# ddr_emif register map
Vendor: Texas Instruments
Peripheral module from a debugger description file (folder Keystone).
Registers are 32-bit, read-write, no defined reset value unless marked. A register's access mark holds for its fields unless they carry their own. Offsets are as the file gives them; lines under a group give offsets from that group; [hi:lo] are bit positions; {n}, {i} and the like mark numbered series; 'fields as' and 'values as' point back to an identical list; <NAME> marks a mode.

## DDR_EMIF
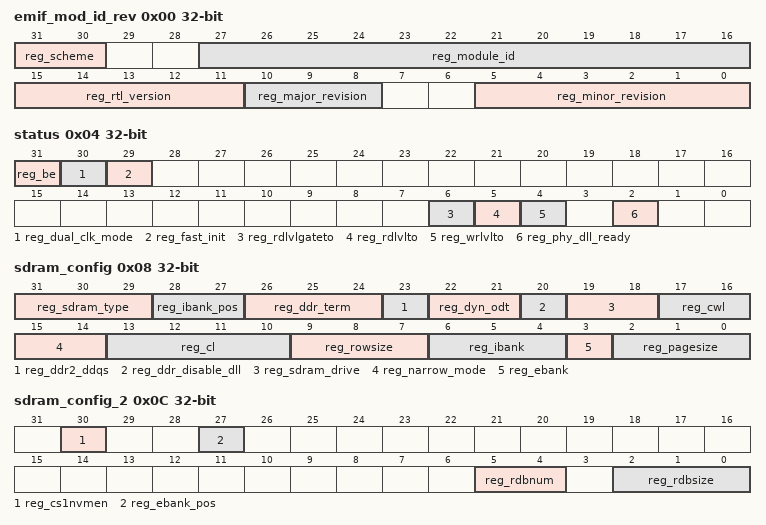
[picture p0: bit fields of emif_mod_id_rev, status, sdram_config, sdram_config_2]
0x00 emif_mod_id_rev
  [31:30] reg_scheme, [27:16] reg_module_id, [15:11] reg_rtl_version, [10:8] reg_major_revision, [5:0] reg_minor_revision
0x04 status
  [31] reg_be, [30] reg_dual_clk_mode, [29] reg_fast_init, [6] reg_rdlvlgateto, [5] reg_rdlvlto, [4] reg_wrlvlto, [2] reg_phy_dll_ready
0x08 sdram_config
  [31:29] reg_sdram_type, [28:27] reg_ibank_pos, [26:24] reg_ddr_term, [23] reg_ddr2_ddqs, [22:21] reg_dyn_odt, [20] reg_ddr_disable_dll, [19:18] reg_sdram_drive, [17:16] reg_cwl, [15:14] reg_narrow_mode, [13:10] reg_cl, [9:7] reg_rowsize, [6:4] reg_ibank, [3] reg_ebank, [2:0] reg_pagesize
0x0C sdram_config_2
  [30] reg_cs1nvmen, [27] reg_ebank_pos, [5:4] reg_rdbnum, [2:0] reg_rdbsize
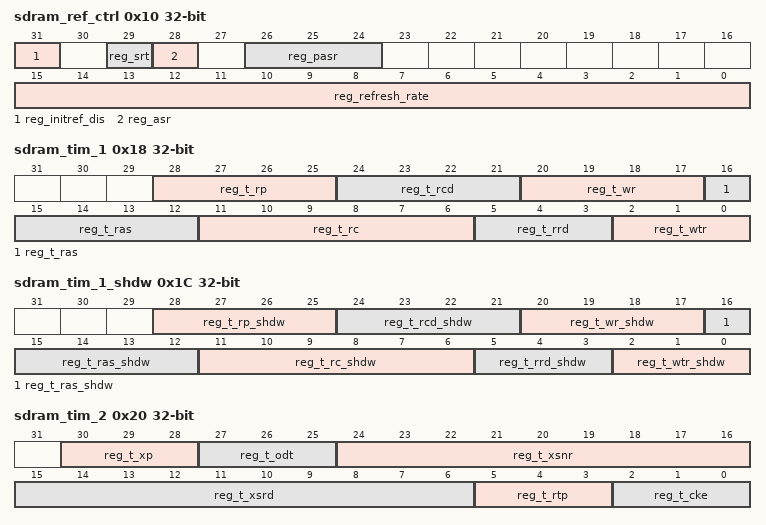
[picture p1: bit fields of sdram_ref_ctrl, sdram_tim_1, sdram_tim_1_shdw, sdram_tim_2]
0x10 sdram_ref_ctrl
  [31] reg_initref_dis, [29] reg_srt, [28] reg_asr, [26:24] reg_pasr, [15:0] reg_refresh_rate
0x14 sdram_ref_ctrl_shdw
  [15:0] reg_refresh_rate_shdw
0x18 sdram_tim_1
  [28:25] reg_t_rp, [24:21] reg_t_rcd, [20:17] reg_t_wr, [16:12] reg_t_ras, [11:6] reg_t_rc, [5:3] reg_t_rrd, [2:0] reg_t_wtr
0x1C sdram_tim_1_shdw
  [28:25] reg_t_rp_shdw, [24:21] reg_t_rcd_shdw, [20:17] reg_t_wr_shdw, [16:12] reg_t_ras_shdw, [11:6] reg_t_rc_shdw, [5:3] reg_t_rrd_shdw, [2:0] reg_t_wtr_shdw
0x20 sdram_tim_2
  [30:28] reg_t_xp, [27:25] reg_t_odt, [24:16] reg_t_xsnr, [15:6] reg_t_xsrd, [5:3] reg_t_rtp, [2:0] reg_t_cke
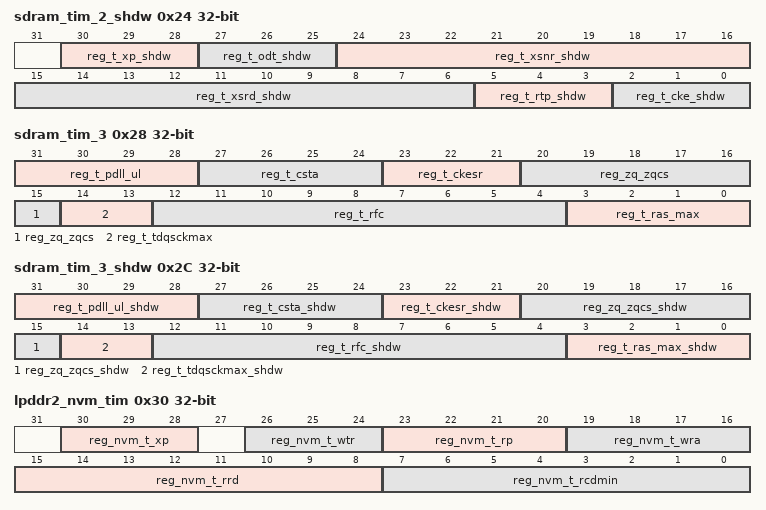
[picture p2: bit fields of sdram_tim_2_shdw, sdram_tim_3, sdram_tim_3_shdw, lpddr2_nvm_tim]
0x24 sdram_tim_2_shdw
  [30:28] reg_t_xp_shdw, [27:25] reg_t_odt_shdw, [24:16] reg_t_xsnr_shdw, [15:6] reg_t_xsrd_shdw, [5:3] reg_t_rtp_shdw, [2:0] reg_t_cke_shdw
0x28 sdram_tim_3
  [31:28] reg_t_pdll_ul, [27:24] reg_t_csta, [23:21] reg_t_ckesr, [20:15] reg_zq_zqcs, [14:13] reg_t_tdqsckmax, [12:4] reg_t_rfc, [3:0] reg_t_ras_max
0x2C sdram_tim_3_shdw
  [31:28] reg_t_pdll_ul_shdw, [27:24] reg_t_csta_shdw, [23:21] reg_t_ckesr_shdw, [20:15] reg_zq_zqcs_shdw, [14:13] reg_t_tdqsckmax_shdw, [12:4] reg_t_rfc_shdw, [3:0] reg_t_ras_max_shdw
0x30 lpddr2_nvm_tim
  [30:28] reg_nvm_t_xp, [26:24] reg_nvm_t_wtr, [23:20] reg_nvm_t_rp, [19:16] reg_nvm_t_wra, [15:8] reg_nvm_t_rrd, [7:0] reg_nvm_t_rcdmin
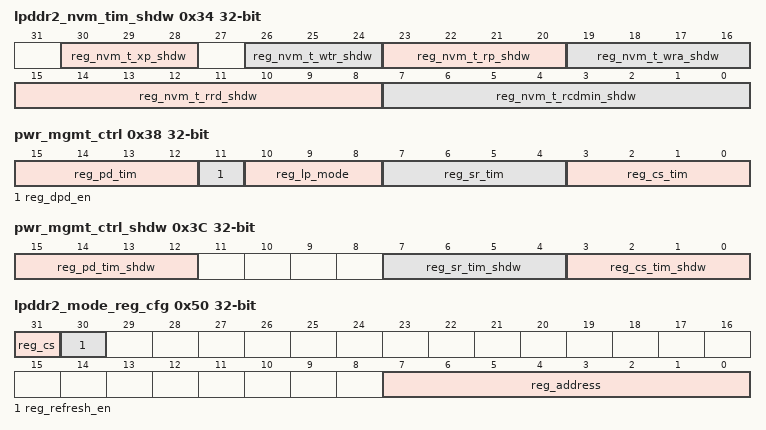
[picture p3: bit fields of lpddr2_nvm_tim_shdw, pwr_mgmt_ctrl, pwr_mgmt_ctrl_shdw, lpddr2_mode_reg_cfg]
0x34 lpddr2_nvm_tim_shdw
  [30:28] reg_nvm_t_xp_shdw, [26:24] reg_nvm_t_wtr_shdw, [23:20] reg_nvm_t_rp_shdw, [19:16] reg_nvm_t_wra_shdw, [15:8] reg_nvm_t_rrd_shdw, [7:0] reg_nvm_t_rcdmin_shdw
0x38 pwr_mgmt_ctrl
  [15:12] reg_pd_tim, [11] reg_dpd_en, [10:8] reg_lp_mode, [7:4] reg_sr_tim, [3:0] reg_cs_tim
0x3C pwr_mgmt_ctrl_shdw
  [15:12] reg_pd_tim_shdw, [7:4] reg_sr_tim_shdw, [3:0] reg_cs_tim_shdw
0x40 lpddr2_mode_reg_data
  [6:0] reg_value_0
0x50 lpddr2_mode_reg_cfg
  [31] reg_cs, [30] reg_refresh_en, [7:0] reg_address
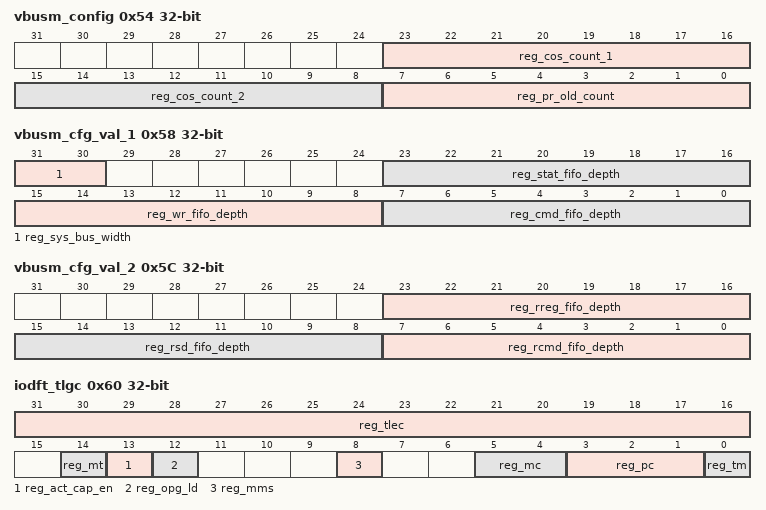
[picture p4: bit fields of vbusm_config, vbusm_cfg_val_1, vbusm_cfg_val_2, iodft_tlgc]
0x54 vbusm_config
  [23:16] reg_cos_count_1, [15:8] reg_cos_count_2, [7:0] reg_pr_old_count
0x58 vbusm_cfg_val_1
  [31:30] reg_sys_bus_width, [23:16] reg_stat_fifo_depth, [15:8] reg_wr_fifo_depth, [7:0] reg_cmd_fifo_depth
0x5C vbusm_cfg_val_2
  [23:16] reg_rreg_fifo_depth, [15:8] reg_rsd_fifo_depth, [7:0] reg_rcmd_fifo_depth
0x60 iodft_tlgc
  [31:16] reg_tlec, [14] reg_mt, [13] reg_act_cap_en, [12] reg_opg_ld, [8] reg_mms, [5:4] reg_mc, [3:1] reg_pc, [0] reg_tm
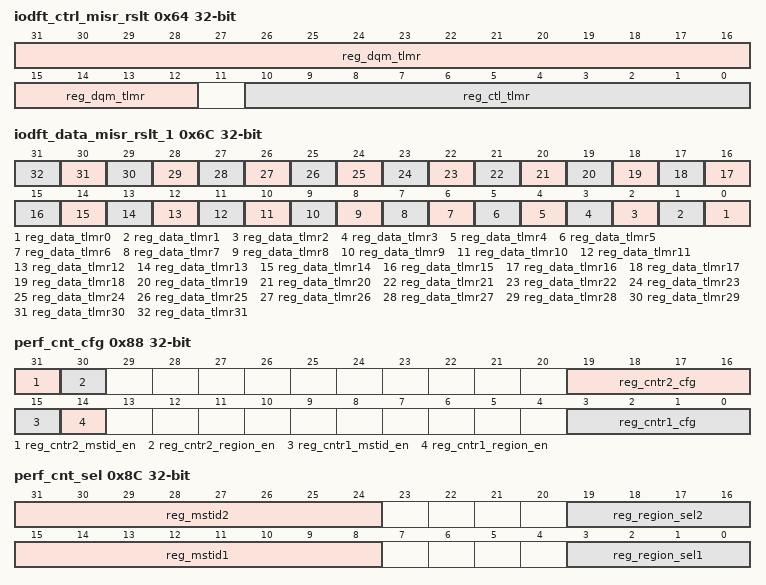
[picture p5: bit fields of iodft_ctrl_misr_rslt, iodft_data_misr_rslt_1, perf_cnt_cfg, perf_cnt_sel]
0x64 iodft_ctrl_misr_rslt
  [31:12] reg_dqm_tlmr, [10:0] reg_ctl_tlmr
0x68 iodft_addr_misr_rslt
  [20:0] reg_addr_tlmr
0x6C iodft_data_misr_rslt_1
  [n] reg_data_tlmr{n} (n=0..31)
{0x68+4i} iodft_data_misr_rslt_{i} access not given (i=2..5)
0x80 perf_cnt_1
  [31:0] reg_counter1
0x84 perf_cnt_2
  [31:0] reg_counter2
0x88 perf_cnt_cfg
  [31] reg_cntr2_mstid_en, [30] reg_cntr2_region_en, [19:16] reg_cntr2_cfg, [15] reg_cntr1_mstid_en, [14] reg_cntr1_region_en, [3:0] reg_cntr1_cfg
0x8C perf_cnt_sel
  [31:24] reg_mstid2, [19:16] reg_region_sel2, [15:8] reg_mstid1, [3:0] reg_region_sel1
0x90 perf_cnt_tim
  [31:0] reg_total_time
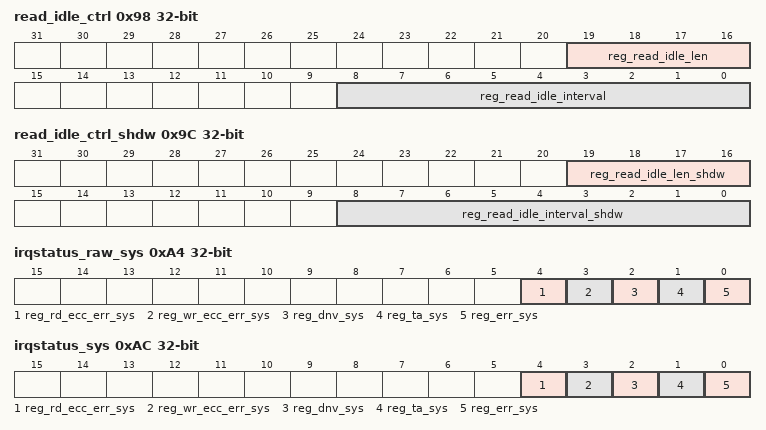
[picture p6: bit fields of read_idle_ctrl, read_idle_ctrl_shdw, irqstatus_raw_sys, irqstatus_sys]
0x98 read_idle_ctrl
  [19:16] reg_read_idle_len, [8:0] reg_read_idle_interval
0x9C read_idle_ctrl_shdw
  [19:16] reg_read_idle_len_shdw, [8:0] reg_read_idle_interval_shdw
0xA4 irqstatus_raw_sys
  [4] reg_rd_ecc_err_sys, [3] reg_wr_ecc_err_sys, [2] reg_dnv_sys, [1] reg_ta_sys, [0] reg_err_sys
0xAC irqstatus_sys
  fields as irqstatus_raw_sys
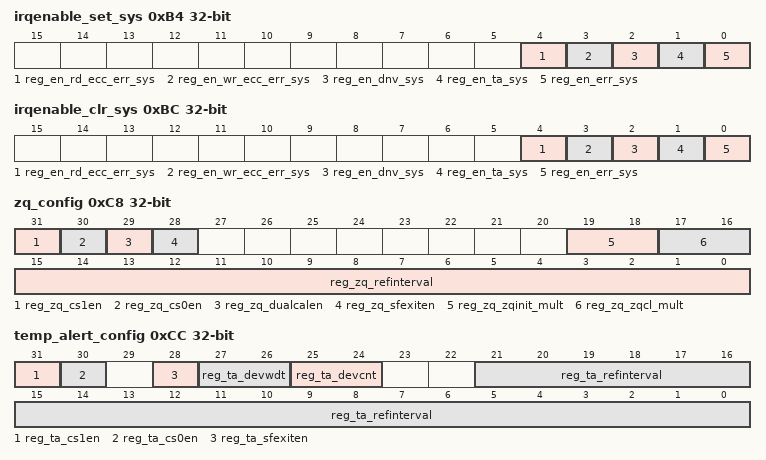
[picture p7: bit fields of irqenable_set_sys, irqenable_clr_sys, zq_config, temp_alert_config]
0xB4 irqenable_set_sys
  [4] reg_en_rd_ecc_err_sys, [3] reg_en_wr_ecc_err_sys, [2] reg_en_dnv_sys, [1] reg_en_ta_sys, [0] reg_en_err_sys
0xBC irqenable_clr_sys
  fields as irqenable_set_sys
0xC8 zq_config
  [31] reg_zq_cs1en, [30] reg_zq_cs0en, [29] reg_zq_dualcalen, [28] reg_zq_sfexiten, [19:18] reg_zq_zqinit_mult, [17:16] reg_zq_zqcl_mult, [15:0] reg_zq_refinterval
0xCC temp_alert_config
  [31] reg_ta_cs1en, [30] reg_ta_cs0en, [28] reg_ta_sfexiten, [27:26] reg_ta_devwdt, [25:24] reg_ta_devcnt, [21:0] reg_ta_refinterval
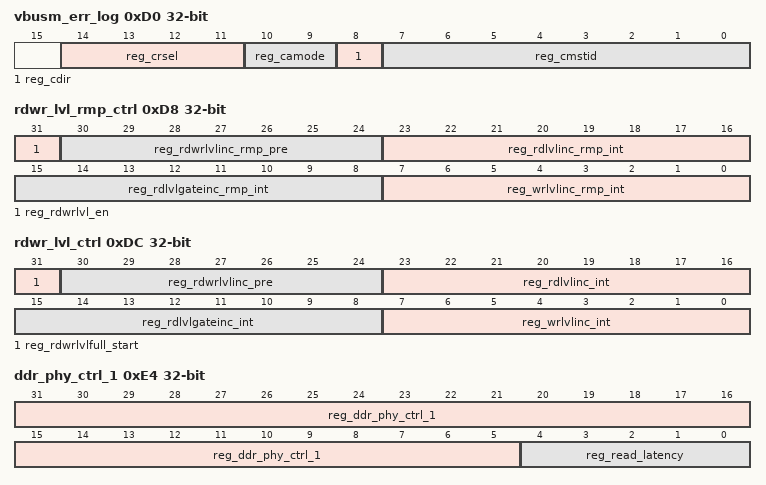
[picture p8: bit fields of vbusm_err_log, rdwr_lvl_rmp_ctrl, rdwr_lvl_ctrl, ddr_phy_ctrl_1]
0xD0 vbusm_err_log
  [14:11] reg_crsel, [10:9] reg_camode, [8] reg_cdir, [7:0] reg_cmstid
0xD4 rdwr_lvl_rmp_win
  [12:0] reg_rdwrlvlinc_rmp_win
0xD8 rdwr_lvl_rmp_ctrl
  [31] reg_rdwrlvl_en, [30:24] reg_rdwrlvlinc_rmp_pre, [23:16] reg_rdlvlinc_rmp_int, [15:8] reg_rdlvlgateinc_rmp_int, [7:0] reg_wrlvlinc_rmp_int
0xDC rdwr_lvl_ctrl
  [31] reg_rdwrlvlfull_start, [30:24] reg_rdwrlvlinc_pre, [23:16] reg_rdlvlinc_int, [15:8] reg_rdlvlgateinc_int, [7:0] reg_wrlvlinc_int
0xE4 ddr_phy_ctrl_1
  [31:5] reg_ddr_phy_ctrl_1, [4:0] reg_read_latency
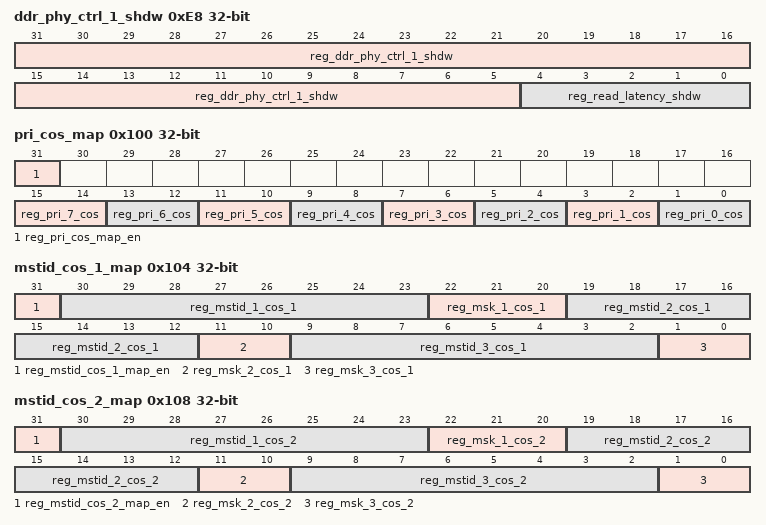
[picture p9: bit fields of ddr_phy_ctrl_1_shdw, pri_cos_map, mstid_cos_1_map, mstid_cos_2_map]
0xE8 ddr_phy_ctrl_1_shdw
  [31:5] reg_ddr_phy_ctrl_1_shdw, [4:0] reg_read_latency_shdw
0xEC ddr_phy_ctrl_2
  [31:0] reg_ddr_phy_ctrl_2
0x100 pri_cos_map
  [31] reg_pri_cos_map_en, [2n+1:2n] reg_pri_{n}_cos (n=0..7)
0x104 mstid_cos_1_map
  [31] reg_mstid_cos_1_map_en, [30:23] reg_mstid_1_cos_1, [22:20] reg_msk_1_cos_1, [19:12] reg_mstid_2_cos_1, [11:10] reg_msk_2_cos_1, [9:2] reg_mstid_3_cos_1, [1:0] reg_msk_3_cos_1
0x108 mstid_cos_2_map
  [31] reg_mstid_cos_2_map_en, [30:23] reg_mstid_1_cos_2, [22:20] reg_msk_1_cos_2, [19:12] reg_mstid_2_cos_2, [11:10] reg_msk_2_cos_2, [9:2] reg_mstid_3_cos_2, [1:0] reg_msk_3_cos_2
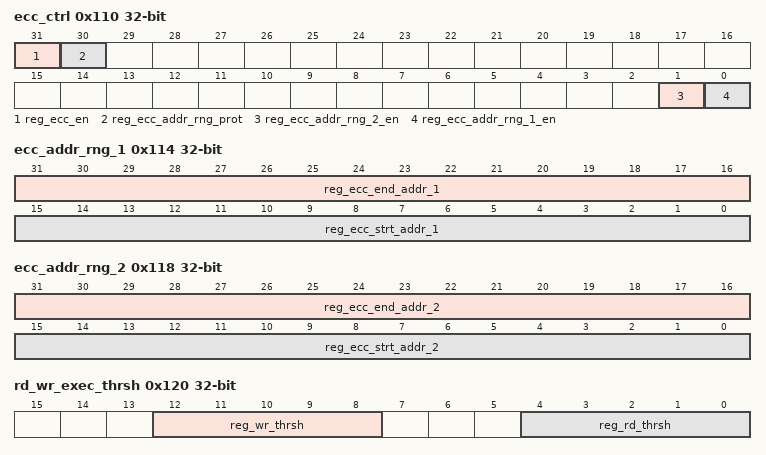
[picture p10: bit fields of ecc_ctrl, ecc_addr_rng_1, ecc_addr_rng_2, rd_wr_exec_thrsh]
0x110 ecc_ctrl
  [31] reg_ecc_en, [30] reg_ecc_addr_rng_prot, [1] reg_ecc_addr_rng_2_en, [0] reg_ecc_addr_rng_1_en
0x114 ecc_addr_rng_1
  [31:16] reg_ecc_end_addr_1, [15:0] reg_ecc_strt_addr_1
0x118 ecc_addr_rng_2
  [31:16] reg_ecc_end_addr_2, [15:0] reg_ecc_strt_addr_2
0x120 rd_wr_exec_thrsh
  [12:8] reg_wr_thrsh, [4:0] reg_rd_thrsh
